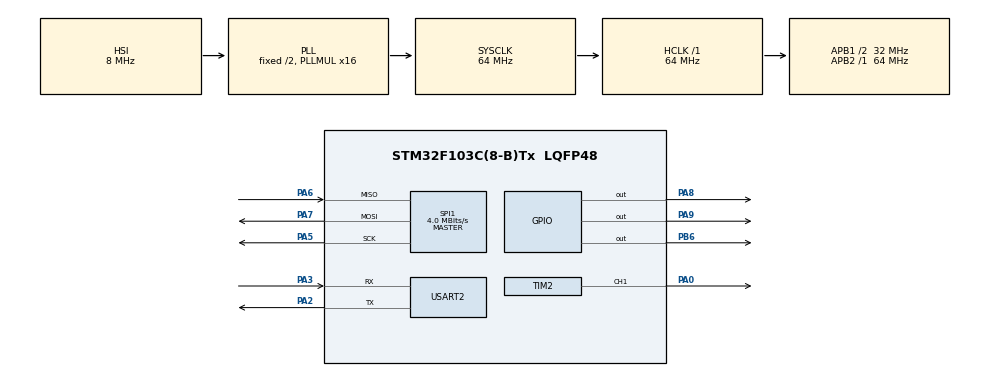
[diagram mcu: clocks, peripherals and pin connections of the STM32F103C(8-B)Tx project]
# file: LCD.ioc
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Mcu.Family=STM32F1
Mcu.Name=STM32F103C(8-B)Tx
Mcu.Package=LQFP48
NVIC.PriorityGroup=NVIC_PRIORITYGROUP_4
PA0-WKUP.Signal=S_TIM2_CH1_ETR
PA13.Mode=Serial_Wire
PA13.Signal=SYS_JTMS-SWDIO
PA14.Mode=Serial_Wire
PA14.Signal=SYS_JTCK-SWCLK
PA2.Mode=Asynchronous
PA2.Signal=USART2_TX
PA3.Mode=Asynchronous
PA3.Signal=USART2_RX
PA5.Mode=Full_Duplex_Master
PA5.Signal=SPI1_SCK
PA6.Mode=Full_Duplex_Master
PA6.Signal=SPI1_MISO
PA7.Mode=Full_Duplex_Master
PA7.Signal=SPI1_MOSI
PA8.Signal=GPIO_Output
PA9.Signal=GPIO_Output
PB6.Signal=GPIO_Output
ProjectManager.HeapSize=0x200
ProjectManager.StackSize=0x400
ProjectManager.TargetToolchain=STM32CubeIDE
RCC.AHBFreq_Value=64000000
RCC.APB1CLKDivider=RCC_HCLK_DIV2
RCC.APB1Freq_Value=32000000
RCC.APB1TimFreq_Value=64000000
RCC.APB2Freq_Value=64000000
RCC.APB2TimFreq_Value=64000000
RCC.HCLKFreq_Value=64000000
RCC.PLLMUL=RCC_PLL_MUL16
RCC.SYSCLKFreq_VALUE=64000000
RCC.SYSCLKSource=RCC_SYSCLKSOURCE_PLLCLK
RCC.USBFreq_Value=64000000
SH.S_TIM2_CH1_ETR.0=TIM2_CH1,PWM Generation1 CH1
SPI1.BaudRatePrescaler=SPI_BAUDRATEPRESCALER_2
SPI1.CalculateBaudRate=4.0 MBits/s
SPI1.DataSize=SPI_DATASIZE_8BIT
SPI1.Direction=SPI_DIRECTION_2LINES
SPI1.Mode=SPI_MODE_MASTER
SPI1.VirtualType=VM_MASTER
TIM2.Channel-PWM\ Generation1\ CH1=TIM_CHANNEL_1
TIM2.OCPolarity_1=TIM_OCPOLARITY_HIGH
TIM2.Prescaler=71
TIM2.Pulse-PWM\ Generation1\ CH1=500
USART2.VirtualMode=VM_ASYNC
board=custom

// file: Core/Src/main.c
/* USER CODE BEGIN Header */
/**
  ******************************************************************************
  * @file           : main.c
  * @brief          : Main program body
  ******************************************************************************
  * @attention
  *
  * Copyright (c) 2024 STMicroelectronics.
  * All rights reserved.
  *
  * This software is licensed under terms that can be found in the LICENSE file
  * in the root directory of this software component.
  * If no LICENSE file comes with this software, it is provided AS-IS.
  *
  ******************************************************************************
  */
/* USER CODE END Header */
#include "main.h"
#include "spi.h"
#include "tim.h"
#include "usart.h"
#include "gpio.h"

/* USER CODE BEGIN Includes */
#include "GUI_Paint.h"
#include "fonts.h"
#include "image.h"
#include "LCD_Test.h"

/* USER CODE END Includes */

void SystemClock_Config(void);

int main(void)
{

  /* MCU Configuration--------------------------------------------------------*/

  /* Reset of all peripherals, Initializes the Flash interface and the Systick. */
  HAL_Init();

  /* Configure the system clock */
  SystemClock_Config();

  /* Initialize all configured peripherals */
  MX_GPIO_Init();
  MX_USART2_UART_Init();
  MX_TIM2_Init();
  MX_SPI1_Init();
  Robot_eyes();

  /* Infinite loop */
  while (1)
  {

  }
}

void SystemClock_Config(void)
{
  RCC_OscInitTypeDef RCC_OscInitStruct = {0};
  RCC_ClkInitTypeDef RCC_ClkInitStruct = {0};

  /** Initializes the RCC Oscillators according to the specified parameters
  * in the RCC_OscInitTypeDef structure.
  */
  RCC_OscInitStruct.OscillatorType = RCC_OSCILLATORTYPE_HSI;
  RCC_OscInitStruct.HSIState = RCC_HSI_ON;
  RCC_OscInitStruct.HSICalibrationValue = RCC_HSICALIBRATION_DEFAULT;
  RCC_OscInitStruct.PLL.PLLState = RCC_PLL_ON;
  RCC_OscInitStruct.PLL.PLLSource = RCC_PLLSOURCE_HSI_DIV2;
  RCC_OscInitStruct.PLL.PLLMUL = RCC_PLL_MUL16;
  if (HAL_RCC_OscConfig(&RCC_OscInitStruct) != HAL_OK)
  {
    Error_Handler();
  }

  /** Initializes the CPU, AHB and APB buses clocks
  */
  RCC_ClkInitStruct.ClockType = RCC_CLOCKTYPE_HCLK|RCC_CLOCKTYPE_SYSCLK
                              |RCC_CLOCKTYPE_PCLK1|RCC_CLOCKTYPE_PCLK2;
  RCC_ClkInitStruct.SYSCLKSource = RCC_SYSCLKSOURCE_PLLCLK;
  RCC_ClkInitStruct.AHBCLKDivider = RCC_SYSCLK_DIV1;
  RCC_ClkInitStruct.APB1CLKDivider = RCC_HCLK_DIV2;
  RCC_ClkInitStruct.APB2CLKDivider = RCC_HCLK_DIV1;

  if (HAL_RCC_ClockConfig(&RCC_ClkInitStruct, FLASH_LATENCY_2) != HAL_OK)
  {
    Error_Handler();
  }
}

void Error_Handler(void)
{
  __disable_irq();
  while (1)
  {
  }
}
